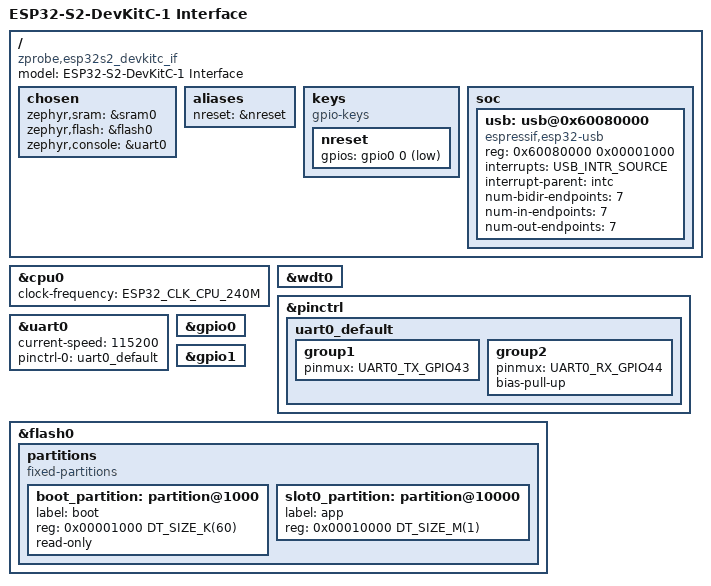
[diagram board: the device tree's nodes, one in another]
/*
 * Copyright (c) 2023 XiNGRZ
 * SPDX-License-Identifier: Apache-2.0
 */

/dts-v1/;
#include <espressif/esp32s2.dtsi>
#include <dt-bindings/pinctrl/esp32s2-pinctrl.h>
#include <zephyr/dt-bindings/pinctrl/esp-pinctrl-common.h>
#include <zephyr/dt-bindings/pinctrl/esp32s2-gpio-sigmap.h>

/ {
	model = "ESP32-S2-DevKitC-1 Interface";
	compatible = "zprobe,esp32s2_devkitc_if", "esp32s2";

	chosen {
		zephyr,sram = &sram0;
		zephyr,flash = &flash0;
		zephyr,console = &uart0;
	};

	aliases {
		nreset = &nreset;
	};

	keys {
		compatible = "gpio-keys";

		nreset: nreset {
			gpios = <&gpio0 0 (GPIO_PULL_UP | GPIO_ACTIVE_LOW)>;
		};
	};
};

&cpu0 {
	clock-frequency = <ESP32_CLK_CPU_240M>;
};

&wdt0 {
	status = "okay";
};

&pinctrl {
	uart0_default: uart0_default {
		group1 {
			pinmux = <UART0_TX_GPIO43>;
		};
		group2 {
			pinmux = <UART0_RX_GPIO44>;
			bias-pull-up;
		};
	};
};

&uart0 {
	status = "okay";
	current-speed = <115200>;
	pinctrl-0 = <&uart0_default>;
	pinctrl-names = "default";
};

&gpio0 {
	status = "okay";
};

&gpio1 {
	status = "okay";
};


&flash0 {
	status = "okay";
	partitions {
		compatible = "fixed-partitions";
		#address-cells = <1>;
		#size-cells = <1>;

		boot_partition: partition@1000 {
			label = "boot";
			reg = <0x00001000 DT_SIZE_K(60)>;
			read-only;
		};

		slot0_partition: partition@10000 {
			label = "app";
			reg = <0x00010000 DT_SIZE_M(1)>;
		};
	};
};

/ {
	soc {
		usb: usb@0x60080000 {
			compatible = "espressif,esp32-usb";
			reg = <0x60080000 0x00001000>;
			interrupts = <USB_INTR_SOURCE>;
			interrupt-parent = <&intc>;
			num-bidir-endpoints = <7>;
			num-in-endpoints = <7>;
			num-out-endpoints = <7>;
		};
	};
};
